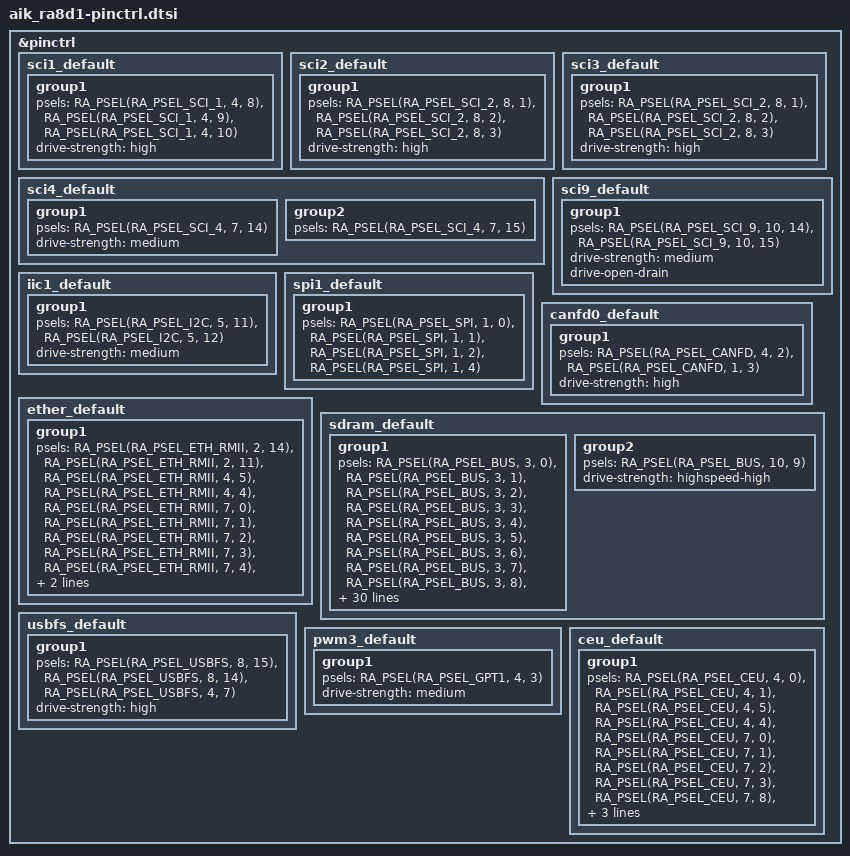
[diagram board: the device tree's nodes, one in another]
/*
 * Copyright (c) 2026 Renesas Electronics Corporation
 *
 * SPDX-License-Identifier: Apache-2.0
 */

&pinctrl {
	sci1_default: sci1_default {
		group1 {
			psels = <RA_PSEL(RA_PSEL_SCI_1, 4, 8)>,  /* MISO/RXD */
				<RA_PSEL(RA_PSEL_SCI_1, 4, 9)>,  /* MOSI/TXD */
				<RA_PSEL(RA_PSEL_SCI_1, 4, 10)>; /* SCK */
			drive-strength = "high";
		};
	};

	sci2_default: sci2_default {
		group1 {
			psels = <RA_PSEL(RA_PSEL_SCI_2, 8, 1)>, /* MISO/RXD */
				<RA_PSEL(RA_PSEL_SCI_2, 8, 2)>, /* MOSI/TXD */
				<RA_PSEL(RA_PSEL_SCI_2, 8, 3)>; /* SCK */
			drive-strength = "high";
		};
	};

	sci3_default: sci3_default {
		group1 {
			psels = <RA_PSEL(RA_PSEL_SCI_2, 8, 1)>, /* MISO/RXD */
				<RA_PSEL(RA_PSEL_SCI_2, 8, 2)>, /* MOSI/TXD */
				<RA_PSEL(RA_PSEL_SCI_2, 8, 3)>; /* SCK */
			drive-strength = "high";
		};
	};

	sci4_default: sci4_default {
		group1 {
			/* TXD */
			psels = <RA_PSEL(RA_PSEL_SCI_4, 7, 14)>;
			drive-strength = "medium";
		};

		group2 {
			/* RXD */
			psels = <RA_PSEL(RA_PSEL_SCI_4, 7, 15)>;
		};
	};

	sci9_default: sci9_default {
		group1 {
			/* SDA, SCL */
			psels = <RA_PSEL(RA_PSEL_SCI_9, 10, 14)>,
				<RA_PSEL(RA_PSEL_SCI_9, 10, 15)>;
			drive-strength = "medium";
			drive-open-drain;
		};
	};

	iic1_default: iic1_default {
		group1 {
			/* SDA, SCL */
			psels = <RA_PSEL(RA_PSEL_I2C, 5, 11)>,
				<RA_PSEL(RA_PSEL_I2C, 5, 12)>;
			drive-strength = "medium";
		};
	};

	spi1_default: spi1_default {
		group1 {
			/* MISO, MOSI, RSPCK, SSL */
			psels = <RA_PSEL(RA_PSEL_SPI, 1, 0)>,
				<RA_PSEL(RA_PSEL_SPI, 1, 1)>,
				<RA_PSEL(RA_PSEL_SPI, 1, 2)>,
				<RA_PSEL(RA_PSEL_SPI, 1, 4)>;
		};
	};

	canfd0_default: canfd0_default {
		group1 {
			/* CRX0 CTX0 */
			psels = <RA_PSEL(RA_PSEL_CANFD, 4, 2)>,
				<RA_PSEL(RA_PSEL_CANFD, 1, 3)>;
			drive-strength = "high";
		};
	};

	ether_default: ether_default {
		group1 {
			psels = <RA_PSEL(RA_PSEL_ETH_RMII, 2, 14)>, /* ET0_MDC */
				<RA_PSEL(RA_PSEL_ETH_RMII, 2, 11)>, /* ET0_MDIO */
				<RA_PSEL(RA_PSEL_ETH_RMII, 4, 5)>, /* RMII0_TXD_EN_B */
				<RA_PSEL(RA_PSEL_ETH_RMII, 4, 4)>, /* RMII0_TXD1_BR */
				<RA_PSEL(RA_PSEL_ETH_RMII, 7, 0)>, /* RMII0_TXD0_B */
				<RA_PSEL(RA_PSEL_ETH_RMII, 7, 1)>, /* REF50CK0_B */
				<RA_PSEL(RA_PSEL_ETH_RMII, 7, 2)>, /* RMII0_RXD0_B */
				<RA_PSEL(RA_PSEL_ETH_RMII, 7, 3)>, /* RMII0_RXD1_B */
				<RA_PSEL(RA_PSEL_ETH_RMII, 7, 4)>, /* RMII0_RX_ER_B */
				<RA_PSEL(RA_PSEL_ETH_RMII, 7, 5)>; /* RMII0_CRS_DV_B */
			drive-strength = "high";
		};
	};

	sdram_default: sdram_default {
		group1 {
			psels = <RA_PSEL(RA_PSEL_BUS, 3, 0)>,	/* SDRAM_A1 */
				<RA_PSEL(RA_PSEL_BUS, 3, 1)>,	/* SDRAM_A2 */
				<RA_PSEL(RA_PSEL_BUS, 3, 2)>,	/* SDRAM_A3 */
				<RA_PSEL(RA_PSEL_BUS, 3, 3)>,	/* SDRAM_A4 */
				<RA_PSEL(RA_PSEL_BUS, 3, 4)>,	/* SDRAM_A5 */
				<RA_PSEL(RA_PSEL_BUS, 3, 5)>,	/* SDRAM_A6 */
				<RA_PSEL(RA_PSEL_BUS, 3, 6)>,	/* SDRAM_A7 */
				<RA_PSEL(RA_PSEL_BUS, 3, 7)>,	/* SDRAM_A8 */
				<RA_PSEL(RA_PSEL_BUS, 3, 8)>,	/* SDRAM_A9 */
				<RA_PSEL(RA_PSEL_BUS, 3, 9)>,	/* SDRAM_A10 */
				<RA_PSEL(RA_PSEL_BUS, 3, 10)>,	/* SDRAM_A11 */
				<RA_PSEL(RA_PSEL_BUS, 3, 11)>,	/* SDRAM_A12 */
				<RA_PSEL(RA_PSEL_BUS, 3, 12)>,	/* SDRAM_A13 */
				<RA_PSEL(RA_PSEL_BUS, 9, 5)>,	/* SDRAM_A14 */
				<RA_PSEL(RA_PSEL_BUS, 9, 6)>,	/* SDRAM_A15 */
				<RA_PSEL(RA_PSEL_BUS, 9, 9)>,	/* SDRAM_CAS */
				<RA_PSEL(RA_PSEL_BUS, 1, 13)>,	/* SDRAM_CKE */
				<RA_PSEL(RA_PSEL_BUS, 6, 1)>,	/* SDRAM_DQ0 */
				<RA_PSEL(RA_PSEL_BUS, 6, 2)>,	/* SDRAM_DQ1 */
				<RA_PSEL(RA_PSEL_BUS, 6, 3)>,	/* SDRAM_DQ2 */
				<RA_PSEL(RA_PSEL_BUS, 6, 4)>,	/* SDRAM_DQ3 */
				<RA_PSEL(RA_PSEL_BUS, 6, 5)>,	/* SDRAM_DQ4 */
				<RA_PSEL(RA_PSEL_BUS, 6, 6)>,	/* SDRAM_DQ5 */
				<RA_PSEL(RA_PSEL_BUS, 6, 7)>,	/* SDRAM_DQ6 */
				<RA_PSEL(RA_PSEL_BUS, 10, 0)>,	/* SDRAM_DQ7 */
				<RA_PSEL(RA_PSEL_BUS, 6, 9)>,	/* SDRAM_DQ8 */
				<RA_PSEL(RA_PSEL_BUS, 6, 10)>,	/* SDRAM_DQ9 */
				<RA_PSEL(RA_PSEL_BUS, 6, 11)>,	/* SDRAM_DQ10 */
				<RA_PSEL(RA_PSEL_BUS, 6, 12)>,	/* SDRAM_DQ11 */
				<RA_PSEL(RA_PSEL_BUS, 6, 13)>,	/* SDRAM_DQ12 */
				<RA_PSEL(RA_PSEL_BUS, 6, 14)>,	/* SDRAM_DQ13 */
				<RA_PSEL(RA_PSEL_BUS, 6, 15)>,	/* SDRAM_DQ14 */
				<RA_PSEL(RA_PSEL_BUS, 10, 8)>,	/* SDRAM_DQ15 */
				<RA_PSEL(RA_PSEL_BUS, 10, 10)>,	/* SDRAM_DQM0 */
				<RA_PSEL(RA_PSEL_BUS, 1, 12)>,	/* SDRAM_DQM1 */
				<RA_PSEL(RA_PSEL_BUS, 9, 8)>,	/* SDRAM_RAS */
				<RA_PSEL(RA_PSEL_BUS, 1, 15)>,	/* SDRAM_SDCS */
				<RA_PSEL(RA_PSEL_BUS, 1, 14)>;	/* SDRAM_WE */
			drive-strength = "high";
		};

		group2 {
			psels = <RA_PSEL(RA_PSEL_BUS, 10, 9)>;	/* SDRAM_SDCLK */
			drive-strength = "highspeed-high";
		};
	};

	usbfs_default: usbfs_default {
		group1 {
			psels = <RA_PSEL(RA_PSEL_USBFS, 8, 15)>, /* USB_DM */
				<RA_PSEL(RA_PSEL_USBFS, 8, 14)>, /* USB_DP */
				<RA_PSEL(RA_PSEL_USBFS, 4, 7)>; /* USB_VBUS */
			drive-strength = "high";
		};
	};

	pwm3_default: pwm3_default {
		group1 {
			psels = <RA_PSEL(RA_PSEL_GPT1, 4, 3)>; /* GTIOC3A */
			drive-strength = "medium";
		};
	};

	ceu_default: ceu_default {
		group1 {
			psels = <RA_PSEL(RA_PSEL_CEU, 4, 0)>,	/* VIO_D0 */
				<RA_PSEL(RA_PSEL_CEU, 4, 1)>,	/* VIO_D1 */
				<RA_PSEL(RA_PSEL_CEU, 4, 5)>,	/* VIO_D2 */
				<RA_PSEL(RA_PSEL_CEU, 4, 4)>,	/* VIO_D3 */
				<RA_PSEL(RA_PSEL_CEU, 7, 0)>,	/* VIO_D4 */
				<RA_PSEL(RA_PSEL_CEU, 7, 1)>,	/* VIO_D5 */
				<RA_PSEL(RA_PSEL_CEU, 7, 2)>,	/* VIO_D6 */
				<RA_PSEL(RA_PSEL_CEU, 7, 3)>,	/* VIO_D7 */
				<RA_PSEL(RA_PSEL_CEU, 7, 8)>,	/* VIO_CLK */
				<RA_PSEL(RA_PSEL_CEU, 7, 9)>,	/* VIO_HD */
				<RA_PSEL(RA_PSEL_CEU, 7, 10)>;	/* VIO_VD */
			drive-strength = "high";
		};
	};
};
